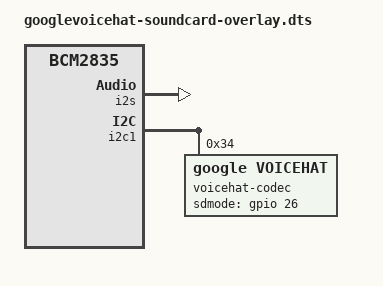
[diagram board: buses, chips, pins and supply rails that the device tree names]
// Definitions for Google voiceHAT v1 soundcard overlay
/dts-v1/;
/plugin/;

/ {
	compatible = "brcm,bcm2835";

	fragment@0 {
		target = <&i2s>;
		__overlay__ {
			status = "okay";
		};
	};

	fragment@1 {
		target = <&gpio>;
		__overlay__ {
			googlevoicehat_pins: googlevoicehat_pins {
				brcm,pins = <26>;
				brcm,function = <1>; /* out */
				brcm,pull = <0>; /* up */
			};
		};
	};

	fragment@2 {
		target = <&i2c1>;
		__overlay__ {
			#address-cells = <1>;
			#size-cells = <0>;
			status = "okay";

			voicehat-codec {
				compatible = "google,voicehat";
				reg = <0x34>;
				#sound-dai-cells = <0>;
                                pinctrl-names = "default";
                                pinctrl-0 = <&googlevoicehat_pins>;
                                sdmode-gpios= <&gpio 26 0>;
			};
		};
	};

	fragment@3 {
		target = <&sound>;
		__overlay__ {
			compatible = "googlevoicehat,googlevoicehat-soundcard";
			i2s-controller = <&i2s>;
			status = "okay";
		};
	};
};
